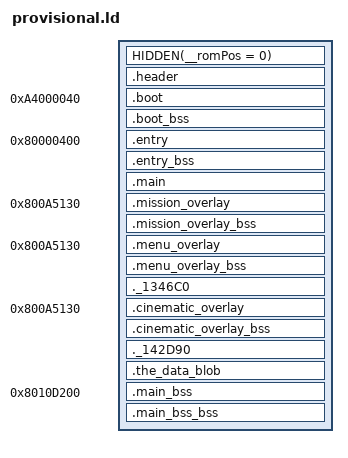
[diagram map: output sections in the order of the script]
SECTIONS
{
    HIDDEN(__romPos = 0);
    header_ROM_START = __romPos;
    header_VRAM = ADDR(.header);
    .header : AT(header_ROM_START) SUBALIGN(16)
    {
        FILL(0x00000000);
        header_DATA_START = .;
        build/asm/header.o(.data);
        header_DATA_END = .;
        header_DATA_SIZE = ABSOLUTE(header_DATA_END - header_DATA_START);
    }
    __romPos += SIZEOF(.header);
    header_ROM_END = __romPos;
    header_VRAM_END = .;

    boot_ROM_START = __romPos;
    boot_VRAM = ADDR(.boot);
    .boot 0xA4000040 : AT(boot_ROM_START) SUBALIGN(16)
    {
        FILL(0x00000000);
        boot_TEXT_START = .;
        build/asm/ipl3_entry.o(.text);
        . = ALIGN(., 16);
        boot_TEXT_END = .;
        boot_TEXT_SIZE = ABSOLUTE(boot_TEXT_END - boot_TEXT_START);
        boot_DATA_START = .;
        build/asm/ipl3_entry.o(.data);
        build/assets/ipl3_font.o(.data);
        . = ALIGN(., 16);
        boot_DATA_END = .;
        boot_DATA_SIZE = ABSOLUTE(boot_DATA_END - boot_DATA_START);
        boot_RODATA_START = .;
        build/asm/ipl3_entry.o(.rodata);
        . = ALIGN(., 16);
        boot_RODATA_END = .;
        boot_RODATA_SIZE = ABSOLUTE(boot_RODATA_END - boot_RODATA_START);
    }
    boot_bss_VRAM = ADDR(.boot_bss);
    .boot_bss (NOLOAD) : SUBALIGN(16)
    {
        FILL(0x00000000);
        boot_BSS_START = .;
        build/asm/ipl3_entry.o(.bss);
        . = ALIGN(., 16);
        boot_BSS_END = .;
        boot_BSS_SIZE = ABSOLUTE(boot_BSS_END - boot_BSS_START);
    }
    __romPos += SIZEOF(.boot);
    __romPos = ALIGN(__romPos, 16);
    . = ALIGN(., 16);
    boot_ROM_END = __romPos;
    boot_VRAM_END = .;

    entry_ROM_START = __romPos;
    entry_VRAM = ADDR(.entry);
    .entry 0x80000400 : AT(entry_ROM_START) SUBALIGN(16)
    {
        FILL(0x00000000);
        entry_TEXT_START = .;
        build/asm/entry_point.o(.text);
        . = ALIGN(., 16);
        entry_TEXT_END = .;
        entry_TEXT_SIZE = ABSOLUTE(entry_TEXT_END - entry_TEXT_START);
        entry_DATA_START = .;
        build/asm/entry_point.o(.data);
        . = ALIGN(., 16);
        entry_DATA_END = .;
        entry_DATA_SIZE = ABSOLUTE(entry_DATA_END - entry_DATA_START);
        entry_RODATA_START = .;
        build/asm/entry_point.o(.rodata);
        . = ALIGN(., 16);
        entry_RODATA_END = .;
        entry_RODATA_SIZE = ABSOLUTE(entry_RODATA_END - entry_RODATA_START);
    }
    entry_bss_VRAM = ADDR(.entry_bss);
    .entry_bss (NOLOAD) : SUBALIGN(16)
    {
        FILL(0x00000000);
        entry_BSS_START = .;
        build/asm/entry_point.o(.bss);
        . = ALIGN(., 16);
        entry_BSS_END = .;
        entry_BSS_SIZE = ABSOLUTE(entry_BSS_END - entry_BSS_START);
    }
    __romPos += SIZEOF(.entry);
    __romPos = ALIGN(__romPos, 16);
    . = ALIGN(., 16);
    entry_ROM_END = __romPos;
    entry_VRAM_END = .;

    main_ROM_START = __romPos;
    main_VRAM = ADDR(.main);
    .main entry_VRAM_END : AT(main_ROM_START) SUBALIGN(16)
    {
        FILL(0x00000000);
        main_RODATA_START = .;
        build/src/main/01720.o(.rodata);
        build/src/main/03310.o(.rodata);
        build/src/main/033C0.o(.rodata);
        build/src/main/03F80.o(.rodata);
        build/src/main/04030.o(.rodata);
        build/src/main/04080.o(.rodata);
        build/src/main/05F80.o(.rodata);
        build/src/main/06170.o(.rodata);
        build/src/main/06560.o(.rodata);
        build/src/main/07800.o(.rodata);
        build/src/main/07F80.o(.rodata);
        build/src/main/080E0.o(.rodata);
        build/src/main/08120.o(.rodata);
        build/src/main/08510.o(.rodata);
        build/asm/main/192E0.o(.rodata);
        build/asm/main/1A410.o(.rodata);
        build/asm/main/1D000.o(.rodata);
        build/asm/main/24570.o(.rodata);
        build/asm/main/24D30.o(.rodata);
        build/asm/main/25480.o(.rodata);
        build/asm/data/main/gspF3DEXMainText.o(.rodata);
        build/src/zlib/adler32.o(.rodata);
        build/asm/data/main/01060.rodata.o(.rodata);
        build/asm/data/main/01070.rodata.o(.rodata);
        build/asm/data/main/01080.rodata.o(.rodata);
        build/asm/data/main/01100.rodata.o(.rodata);
        build/asm/data/main/01120.rodata.o(.rodata);
        build/asm/data/main/013D0.rodata.o(.rodata);
        build/asm/data/main/013F0.rodata.o(.rodata);
        build/asm/data/main/01410.rodata.o(.rodata);
        build/asm/data/main/01590.rodata.o(.rodata);
        build/asm/data/main/01600.rodata.o(.rodata);
        build/src/zlib/inflate.o(.rodata);
        build/src/zlib/infblock.o(.rodata);
        build/src/zlib/infcodes.o(.rodata);
        build/src/zlib/inffast.o(.rodata);
        build/src/zlib/inftrees.o(.rodata);
        build/src/zlib/infutil.o(.rodata);
        build/src/zlib/zutil.o(.rodata);
        build/asm/libultra/io/aisetfreq.o(.rodata);
        build/asm/libultra/io/aisetnextbuf.o(.rodata);
        build/asm/libultra/io/ai.o(.rodata);
        build/asm/libultra/libc/bcmp.o(.rodata);
        build/asm/libultra/libc/bzero.o(.rodata);
        build/asm/libultra/io/conteeplongread.o(.rodata);
        build/asm/libultra/io/conteeplongwrite.o(.rodata);
        build/asm/libultra/io/conteepprobe.o(.rodata);
        build/asm/libultra/io/conteepread.o(.rodata);
        build/asm/libultra/io/conteepwrite.o(.rodata);
        build/asm/libultra/io/contquery.o(.rodata);
        build/asm/libultra/io/contreaddata.o(.rodata);
        build/asm/libultra/io/controller.o(.rodata);
        main_TEXT_START = .;
        build/src/main/01720.o(.text);
        build/src/main/03310.o(.text);
        build/src/main/033C0.o(.text);
        build/src/main/03F80.o(.text);
        build/src/main/04030.o(.text);
        build/src/main/04030.o(.data);
        build/src/main/04080.o(.text);
        build/src/main/05F80.o(.text);
        build/src/main/06170.o(.text);
        build/src/main/06560.o(.text);
        build/src/main/07800.o(.text);
        build/src/main/07F80.o(.text);
        build/src/main/080E0.o(.text);
        build/src/main/08120.o(.text);
        build/src/main/08510.o(.text);
        build/asm/main/192E0.o(.text);
        build/asm/main/1A410.o(.text);
        build/asm/main/1D000.o(.text);
        build/asm/main/24570.o(.text);
        build/asm/main/24D30.o(.text);
        build/asm/main/25480.o(.text);
        build/asm/data/main/gspF3DEXMainText.o(.text);
        build/src/zlib/adler32.o(.text);
        build/src/zlib/inflate.o(.text);
        build/src/zlib/infblock.o(.text);
        build/src/zlib/infcodes.o(.text);
        build/src/zlib/inffast.o(.text);
        build/src/zlib/inftrees.o(.text);
        build/src/zlib/infutil.o(.text);
        build/src/zlib/zutil.o(.text);
        build/asm/libultra/io/aisetfreq.o(.text);
        build/asm/libultra/io/aisetnextbuf.o(.text);
        build/asm/libultra/io/ai.o(.text);
        build/asm/libultra/libc/bcmp.o(.text);
        build/asm/libultra/libc/bzero.o(.text);
        build/asm/libultra/io/conteeplongread.o(.text);
        build/asm/libultra/io/conteeplongwrite.o(.text);
        build/asm/libultra/io/conteepprobe.o(.text);
        build/asm/libultra/io/conteepread.o(.text);
        build/asm/libultra/io/conteepwrite.o(.text);
        build/asm/libultra/io/contquery.o(.text);
        build/asm/libultra/io/contreaddata.o(.text);
        build/asm/libultra/io/controller.o(.text);
        build/asm/libultra/gu/cosf.o(.text);
        build/asm/libultra/os/createmesgqueue.o(.text);
        build/asm/libultra/os/createthread.o(.text);
        build/asm/libultra/os/destroythread.o(.text);
        build/asm/libultra/io/dpctr.o(.text);
        build/asm/libultra/io/dpsetstat.o(.text);
        build/asm/libultra/os/exceptasm.o(.text);
        build/asm/libultra/os/gettime.o(.text);
        build/asm/libultra/os/getcount.o(.text);
        build/asm/libultra/os/initialize.o(.text);
        build/asm/libultra/os/getsr.o(.text);
        build/asm/libultra/os/interrupt.o(.text);
        build/asm/libultra/os/invaldcache.o(.text);
        build/asm/libultra/os/invalicache.o(.text);
        build/asm/libultra/os/jammesg.o(.text);
        build/asm/libultra/io/leointerrupt.o(.text);
        build/asm/libultra/io/epirawdma.o(.text);
        build/asm/libultra/io/leodiskinit.o(.text);
        build/asm/libultra/libc/ll.o(.text);
        build/asm/libultra/os/maptlbrdb.o(.text);
        build/asm/libultra/io/motor.o(.text);
        build/asm/libultra/io/contramread.o(.text);
        build/asm/libultra/io/contramwrite.o(.text);
        build/asm/libultra/io/crc.o(.text);
        build/asm/libultra/gu/mtxcatl.o(.text);
        build/asm/libultra/gu/mtxcatf.o(.text);
        build/asm/libultra/gu/mtxutil.o(.text);
        build/asm/libultra/gu/perspective.o(.text);
        build/asm/libultra/io/pfsallocatefile.o(.text);
        build/asm/libultra/io/contpfs.o(.text);
        build/asm/libultra/io/pfsdeletefile.o(.text);
        build/asm/libultra/io/pfsfreeblocks.o(.text);
        build/asm/libultra/io/pfsgetstatus.o(.text);
        build/asm/libultra/io/pfsinitpak.o(.text);
        build/asm/libultra/io/pfschecker.o(.text);
        build/asm/libultra/io/pfsisplug.o(.text);
        build/asm/libultra/io/pfsreadwritefile.o(.text);
        build/asm/libultra/io/pfsrepairid.o(.text);
        build/asm/libultra/io/pfssearchfile.o(.text);
        build/asm/libultra/io/pidma.o(.text);
        build/asm/libultra/io/pigetcmdq.o(.text);
        build/asm/libultra/io/pimgr.o(.text);
        build/asm/libultra/io/cartrominit.o(.text);
        build/asm/libultra/io/devmgr.o(.text);
        build/asm/libultra/io/epirawread.o(.text);
        build/asm/libultra/io/epirawwrite.o(.text);
        build/asm/libultra/os/getthreadpri.o(.text);
        build/asm/libultra/io/piacs.o(.text);
        build/asm/libultra/io/pirawdma.o(.text);
        build/asm/libultra/io/pirawread.o(.text);
        build/asm/libultra/os/recvmesg.o(.text);
        build/asm/libultra/os/resetglobalintmask.o(.text);
        build/asm/libultra/gu/scale.o(.text);
        build/asm/libultra/os/sendmesg.o(.text);
        build/asm/libultra/os/seteventmesg.o(.text);
        build/asm/libultra/os/setfpccsr.o(.text);
        build/asm/libultra/os/setglobalintmask.o(.text);
        build/asm/libultra/os/setintmask.o(.text);
        build/asm/libultra/os/setsr.o(.text);
        build/asm/libultra/os/setthreadpri.o(.text);
        build/asm/libultra/os/settimer.o(.text);
        build/asm/libultra/io/siacs.o(.text);
        build/asm/libultra/gu/sinf.o(.text);
        build/asm/libultra/io/sirawdma.o(.text);
        build/asm/libultra/io/si.o(.text);
        build/asm/libultra/io/sirawread.o(.text);
        build/asm/libultra/io/sirawwrite.o(.text);
        build/asm/libultra/libc/sprintf.o(.text);
        build/asm/libultra/io/sptask.o(.text);
        build/asm/libultra/libc/bcopy.o(.text);
        build/asm/libultra/io/sp.o(.text);
        build/asm/libultra/io/sprawdma.o(.text);
        build/asm/libultra/io/spsetpc.o(.text);
        build/asm/libultra/io/spsetstat.o(.text);
        build/asm/libultra/io/sptaskyield.o(.text);
        build/asm/libultra/io/sptaskyielded.o(.text);
        build/asm/libultra/io/spgetstat.o(.text);
        build/asm/libultra/os/startthread.o(.text);
        build/asm/libultra/os/stopthread.o(.text);
        build/asm/libultra/libc/string.o(.text);
        build/asm/libultra/os/thread.o(.text);
        build/asm/libultra/os/timerintr.o(.text);
        build/asm/libultra/os/setcompare.o(.text);
        build/asm/libultra/io/viblack.o(.text);
        build/asm/libultra/io/vi.o(.text);
        build/asm/libultra/io/vigetfield.o(.text);
        build/asm/libultra/io/vimgr.o(.text);
        build/asm/libultra/io/vigetcurrcontext.o(.text);
        build/asm/libultra/os/virtualtophysical.o(.text);
        build/asm/libultra/os/probetlb.o(.text);
        build/asm/libultra/io/visetevent.o(.text);
        build/asm/libultra/io/visetmode.o(.text);
        build/asm/libultra/io/visetspecial.o(.text);
        build/asm/libultra/io/viswapbuf.o(.text);
        build/asm/libultra/io/viswapcontext.o(.text);
        build/asm/libultra/os/writebackdcache.o(.text);
        build/asm/libultra/os/writebackdcacheall.o(.text);
        build/asm/libultra/libc/xprintf.o(.text);
        build/asm/libultra/libc/xldtob.o(.text);
        build/asm/libultra/libc/ldiv.o(.text);
        build/asm/libultra/libc/xlitob.o(.text);
        build/asm/libultra/os/yieldthread.o(.text);
        main_DATA_START = .;
        build/asm/data/main/38160.data.o(.data);
        build/asm/data/main/381B0.data.o(.data);
        build/asm/data/main/381C0.data.o(.data);
        build/asm/data/main/38220.data.o(.data);
        build/asm/data/main/38230.data.o(.data);
        build/asm/data/main/38240.data.o(.data);
        build/asm/data/main/38250.data.o(.data);
        build/asm/data/main/383C0.data.o(.data);
        build/asm/data/main/39460.data.o(.data);
        build/asm/data/main/394E0.data.o(.data);
        build/asm/data/main/398F0.data.o(.data);
        build/asm/data/main/gspF3DEXMainData.o(.data);
        build/asm/data/zlib/infblock.data.o(.data);
        build/src/zlib/infcodes.o(.data);
        build/src/zlib/inffast.o(.data);
        build/asm/data/zlib/inftrees.data.o(.data);
        build/asm/data/zlib/infutil.data.o(.data);
        build/asm/data/zlib/zutil.data.o(.data);
        build/asm/libultra/io/aisetfreq.o(.data);
        build/asm/data/libultra/io/aisetnextbuf.data.o(.data);
        build/asm/libultra/io/ai.o(.data);
        build/asm/libultra/libc/bcmp.o(.data);
        build/asm/libultra/libc/bzero.o(.data);
        build/asm/libultra/io/conteeplongread.o(.data);
        build/asm/libultra/io/conteeplongwrite.o(.data);
        build/asm/libultra/io/conteepprobe.o(.data);
        build/asm/libultra/io/conteepread.o(.data);
        build/asm/libultra/io/conteepwrite.o(.data);
        build/asm/libultra/io/contquery.o(.data);
        build/asm/libultra/io/contreaddata.o(.data);
        build/asm/data/libultra/io/controller.data.o(.data);
        build/asm/libultra/gu/cosf.o(.data);
        build/asm/libultra/os/createmesgqueue.o(.data);
        build/asm/libultra/os/createthread.o(.data);
        build/asm/libultra/os/destroythread.o(.data);
        build/asm/libultra/io/dpctr.o(.data);
        build/asm/libultra/io/dpsetstat.o(.data);
        build/asm/data/libultra/os/exceptasm.data.o(.data);
        build/asm/libultra/os/gettime.o(.data);
        build/asm/libultra/os/getcount.o(.data);
        build/asm/data/libultra/os/initialize.data.o(.data);
        build/asm/libultra/os/getsr.o(.data);
        build/asm/libultra/os/interrupt.o(.data);
        build/asm/libultra/os/invaldcache.o(.data);
        build/asm/libultra/os/invalicache.o(.data);
        build/asm/libultra/os/jammesg.o(.data);
        build/asm/libultra/io/leointerrupt.o(.data);
        build/asm/libultra/io/epirawdma.o(.data);
        build/asm/libultra/io/leodiskinit.o(.data);
        build/asm/libultra/libc/ll.o(.data);
        build/asm/libultra/os/maptlbrdb.o(.data);
        build/asm/data/libultra/io/motor.data.o(.data);
        build/asm/libultra/io/contramread.o(.data);
        build/asm/libultra/io/contramwrite.o(.data);
        build/asm/libultra/io/crc.o(.data);
        build/asm/libultra/gu/mtxcatl.o(.data);
        build/asm/libultra/gu/mtxcatf.o(.data);
        build/asm/libultra/gu/mtxutil.o(.data);
        build/asm/libultra/gu/perspective.o(.data);
        build/asm/libultra/io/pfsallocatefile.o(.data);
        build/asm/libultra/io/contpfs.o(.data);
        build/asm/libultra/io/pfsdeletefile.o(.data);
        build/asm/libultra/io/pfsfreeblocks.o(.data);
        build/asm/libultra/io/pfsgetstatus.o(.data);
        build/asm/libultra/io/pfsinitpak.o(.data);
        build/asm/libultra/io/pfschecker.o(.data);
        build/asm/libultra/io/pfsisplug.o(.data);
        build/asm/libultra/io/pfsreadwritefile.o(.data);
        build/asm/libultra/io/pfsrepairid.o(.data);
        build/asm/libultra/io/pfssearchfile.o(.data);
        build/asm/libultra/io/pidma.o(.data);
        build/asm/libultra/io/pigetcmdq.o(.data);
        build/asm/data/libultra/io/pimgr.data.o(.data);
        build/asm/libultra/io/cartrominit.o(.data);
        build/asm/libultra/io/devmgr.o(.data);
        build/asm/libultra/io/epirawread.o(.data);
        build/asm/libultra/io/epirawwrite.o(.data);
        build/asm/libultra/os/getthreadpri.o(.data);
        build/asm/data/libultra/io/piacs.data.o(.data);
        build/asm/libultra/io/pirawdma.o(.data);
        build/asm/libultra/io/pirawread.o(.data);
        build/asm/libultra/os/recvmesg.o(.data);
        build/asm/libultra/os/resetglobalintmask.o(.data);
        build/asm/libultra/gu/scale.o(.data);
        build/asm/libultra/os/sendmesg.o(.data);
        build/asm/libultra/os/seteventmesg.o(.data);
        build/asm/libultra/os/setfpccsr.o(.data);
        build/asm/libultra/os/setglobalintmask.o(.data);
        build/asm/libultra/os/setintmask.o(.data);
        build/asm/libultra/os/setsr.o(.data);
        build/asm/libultra/os/setthreadpri.o(.data);
        build/asm/libultra/os/settimer.o(.data);
        build/asm/data/libultra/io/siacs.data.o(.data);
        build/asm/libultra/gu/sinf.o(.data);
        build/asm/libultra/io/sirawdma.o(.data);
        build/asm/libultra/io/si.o(.data);
        build/asm/libultra/io/sirawread.o(.data);
        build/asm/libultra/io/sirawwrite.o(.data);
        build/asm/libultra/libc/sprintf.o(.data);
        build/asm/libultra/io/sptask.o(.data);
        build/asm/libultra/libc/bcopy.o(.data);
        build/asm/libultra/io/sp.o(.data);
        build/asm/libultra/io/sprawdma.o(.data);
        build/asm/libultra/io/spsetpc.o(.data);
        build/asm/libultra/io/spsetstat.o(.data);
        build/asm/libultra/io/sptaskyield.o(.data);
        build/asm/libultra/io/sptaskyielded.o(.data);
        build/asm/libultra/io/spgetstat.o(.data);
        build/asm/libultra/os/startthread.o(.data);
        build/asm/libultra/os/stopthread.o(.data);
        build/asm/libultra/libc/string.o(.data);
        build/asm/data/libultra/os/thread.data.o(.data);
        build/asm/data/libultra/os/timerintr.data.o(.data);
        build/asm/libultra/os/setcompare.o(.data);
        build/asm/libultra/io/viblack.o(.data);
        build/asm/data/libultra/io/vi.data.o(.data);
        build/asm/libultra/io/vigetfield.o(.data);
        build/asm/data/libultra/io/vimgr.data.o(.data);
        build/asm/libultra/io/vigetcurrcontext.o(.data);
        build/asm/libultra/os/virtualtophysical.o(.data);
        build/asm/libultra/os/probetlb.o(.data);
        build/asm/libultra/io/visetevent.o(.data);
        build/asm/libultra/io/visetmode.o(.data);
        build/asm/libultra/io/visetspecial.o(.data);
        build/asm/libultra/io/viswapbuf.o(.data);
        build/asm/libultra/io/viswapcontext.o(.data);
        build/asm/libultra/os/writebackdcache.o(.data);
        build/asm/libultra/os/writebackdcacheall.o(.data);
        build/asm/data/libultra/vimodes/vimodempallan1.data.o(.data);
        build/asm/data/libultra/vimodes/vimodentsclan1.data.o(.data);
        build/asm/data/libultra/vimodes/vimodepallan1.data.o(.data);
        build/asm/data/libultra/io/vitbl.data.o(.data);
        build/asm/data/libultra/libc/xprintf.data.o(.data);
        build/asm/libultra/libc/xldtob.o(.data);
        build/asm/libultra/libc/ldiv.o(.data);
        build/asm/data/libultra/libc/xlitob.data.o(.data);
        build/asm/libultra/os/yieldthread.o(.data);
        build/asm/data/main/rspbootText.o(.data);
        build/asm/main/832A0.o(.data);
        build/asm/main/94A80.o(.data);
        build/asm/main/94F50.o(.data);
        build/asm/main/97D20.o(.data);
        build/asm/main/98960.o(.data);
        build/asm/main/9A850.o(.data);
        build/asm/data/main/aspMainText.o(.data);
        build/asm/main/9BB60.o(.data);
        build/asm/main/9CED0.o(.data);
        build/asm/main/9E3D0.o(.data);
        build/asm/data/libultra/gu/cosf.rodata.o(.rodata);
        build/asm/libultra/os/createmesgqueue.o(.rodata);
        build/asm/libultra/os/createthread.o(.rodata);
        build/asm/libultra/os/destroythread.o(.rodata);
        build/asm/libultra/io/dpctr.o(.rodata);
        build/asm/libultra/io/dpsetstat.o(.rodata);
        build/asm/data/libultra/os/exceptasm.rodata.o(.rodata);
        build/asm/libultra/os/gettime.o(.rodata);
        build/asm/libultra/os/getcount.o(.rodata);
        build/asm/libultra/os/initialize.o(.rodata);
        build/asm/libultra/os/getsr.o(.rodata);
        build/asm/libultra/os/interrupt.o(.rodata);
        build/asm/libultra/os/invaldcache.o(.rodata);
        build/asm/libultra/os/invalicache.o(.rodata);
        build/asm/libultra/os/jammesg.o(.rodata);
        build/asm/libultra/io/leointerrupt.o(.rodata);
        build/asm/libultra/io/epirawdma.o(.rodata);
        build/asm/libultra/io/leodiskinit.o(.rodata);
        build/asm/libultra/libc/ll.o(.rodata);
        build/asm/libultra/os/maptlbrdb.o(.rodata);
        build/asm/libultra/io/motor.o(.rodata);
        build/asm/libultra/io/contramread.o(.rodata);
        build/asm/libultra/io/contramwrite.o(.rodata);
        build/asm/libultra/io/crc.o(.rodata);
        build/asm/libultra/gu/mtxcatl.o(.rodata);
        build/asm/libultra/gu/mtxcatf.o(.rodata);
        build/asm/libultra/gu/mtxutil.o(.rodata);
        build/asm/data/libultra/gu/libm_vals.rodata.o(.rodata);
        build/asm/data/libultra/gu/perspective.rodata.o(.rodata);
        build/asm/libultra/io/pfsallocatefile.o(.rodata);
        build/asm/libultra/io/contpfs.o(.rodata);
        build/asm/libultra/io/pfsdeletefile.o(.rodata);
        build/asm/libultra/io/pfsfreeblocks.o(.rodata);
        build/asm/libultra/io/pfsgetstatus.o(.rodata);
        build/asm/libultra/io/pfsinitpak.o(.rodata);
        build/asm/libultra/io/pfschecker.o(.rodata);
        build/asm/libultra/io/pfsisplug.o(.rodata);
        build/asm/libultra/io/pfsreadwritefile.o(.rodata);
        build/asm/libultra/io/pfsrepairid.o(.rodata);
        build/asm/libultra/io/pfssearchfile.o(.rodata);
        build/asm/libultra/io/pidma.o(.rodata);
        build/asm/libultra/io/pigetcmdq.o(.rodata);
        build/asm/libultra/io/pimgr.o(.rodata);
        build/asm/libultra/io/cartrominit.o(.rodata);
        build/asm/data/libultra/io/devmgr.rodata.o(.rodata);
        build/asm/libultra/io/epirawread.o(.rodata);
        build/asm/libultra/io/epirawwrite.o(.rodata);
        build/asm/libultra/os/getthreadpri.o(.rodata);
        build/asm/libultra/io/piacs.o(.rodata);
        build/asm/libultra/io/pirawdma.o(.rodata);
        build/asm/libultra/io/pirawread.o(.rodata);
        build/asm/libultra/os/recvmesg.o(.rodata);
        build/asm/libultra/os/resetglobalintmask.o(.rodata);
        build/asm/libultra/gu/scale.o(.rodata);
        build/asm/libultra/os/sendmesg.o(.rodata);
        build/asm/libultra/os/seteventmesg.o(.rodata);
        build/asm/libultra/os/setfpccsr.o(.rodata);
        build/asm/libultra/os/setglobalintmask.o(.rodata);
        build/asm/data/libultra/os/setintmask.rodata.o(.rodata);
        build/asm/libultra/os/setsr.o(.rodata);
        build/asm/libultra/os/setthreadpri.o(.rodata);
        build/asm/libultra/os/settimer.o(.rodata);
        build/asm/libultra/io/siacs.o(.rodata);
        build/asm/data/libultra/gu/sinf.rodata.o(.rodata);
        build/asm/libultra/io/sirawdma.o(.rodata);
        build/asm/libultra/io/si.o(.rodata);
        build/asm/libultra/io/sirawread.o(.rodata);
        build/asm/libultra/io/sirawwrite.o(.rodata);
        build/asm/libultra/libc/sprintf.o(.rodata);
        build/asm/libultra/io/sptask.o(.rodata);
        build/asm/libultra/libc/bcopy.o(.rodata);
        build/asm/libultra/io/sp.o(.rodata);
        build/asm/libultra/io/sprawdma.o(.rodata);
        build/asm/libultra/io/spsetpc.o(.rodata);
        build/asm/libultra/io/spsetstat.o(.rodata);
        build/asm/libultra/io/sptaskyield.o(.rodata);
        build/asm/libultra/io/sptaskyielded.o(.rodata);
        build/asm/libultra/io/spgetstat.o(.rodata);
        build/asm/libultra/os/startthread.o(.rodata);
        build/asm/libultra/os/stopthread.o(.rodata);
        build/asm/libultra/libc/string.o(.rodata);
        build/asm/libultra/os/thread.o(.rodata);
        build/asm/libultra/os/timerintr.o(.rodata);
        build/asm/libultra/os/setcompare.o(.rodata);
        build/asm/libultra/io/viblack.o(.rodata);
        build/asm/libultra/io/vi.o(.rodata);
        build/asm/libultra/io/vigetfield.o(.rodata);
        build/asm/libultra/io/vimgr.o(.rodata);
        build/asm/libultra/io/vigetcurrcontext.o(.rodata);
        build/asm/libultra/os/virtualtophysical.o(.rodata);
        build/asm/libultra/os/probetlb.o(.rodata);
        build/asm/libultra/io/visetevent.o(.rodata);
        build/asm/libultra/io/visetmode.o(.rodata);
        build/asm/libultra/io/visetspecial.o(.rodata);
        build/asm/libultra/io/viswapbuf.o(.rodata);
        build/asm/libultra/io/viswapcontext.o(.rodata);
        build/asm/libultra/os/writebackdcache.o(.rodata);
        build/asm/libultra/os/writebackdcacheall.o(.rodata);
        build/asm/data/libultra/libc/xprintf.rodata.o(.rodata);
        build/asm/data/libultra/libc/xldtob.rodata.o(.rodata);
        build/asm/libultra/libc/ldiv.o(.rodata);
        build/asm/libultra/libc/xlitob.o(.rodata);
        build/asm/libultra/os/yieldthread.o(.rodata);
        build/asm/data/main/rspbootText.o(.rodata);
        build/asm/main/832A0.o(.rodata);
        build/asm/main/94A80.o(.rodata);
        build/asm/main/94F50.o(.rodata);
        build/asm/main/97D20.o(.rodata);
        build/asm/main/98960.o(.rodata);
        build/asm/main/9A850.o(.rodata);
        build/asm/data/main/aspMainText.o(.rodata);
        build/asm/main/9BB60.o(.rodata);
        build/asm/main/9CED0.o(.rodata);
        build/asm/main/9E3D0.o(.rodata);
        build/asm/data/main/3AFE0.rodata.o(.rodata);
        build/asm/data/main/3B0D0.rodata.o(.rodata);
        build/asm/data/main/3B210.rodata.o(.rodata);
        build/asm/data/main/3B240.rodata.o(.rodata);
        build/asm/data/main/3B3E0.rodata.o(.rodata);
        build/asm/data/main/3B420.rodata.o(.rodata);
        build/asm/data/main/3B4C0.rodata.o(.rodata);
        build/asm/data/main/3B4D0.rodata.o(.rodata);
        build/asm/data/main/3B7E0.rodata.o(.rodata);
        build/asm/data/main/3B8D0.rodata.o(.rodata);
        build/asm/data/main/3B920.rodata.o(.rodata);
        build/asm/data/main/3B9C0.rodata.o(.rodata);
        build/asm/data/main/3BE30.rodata.o(.rodata);
        build/asm/data/main/3BF00.rodata.o(.rodata);
        build/asm/data/main/3C010.rodata.o(.rodata);
        build/asm/data/main/3C430.rodata.o(.rodata);
        build/asm/data/main/3CE60.rodata.o(.rodata);
        build/asm/data/main/3CEE0.rodata.o(.rodata);
        build/asm/data/main/3D3D0.rodata.o(.rodata);
        build/asm/data/main/3D4D0.rodata.o(.rodata);
        build/src/main/6B8B0.o(.rodata);
        build/asm/data/main/3D560.rodata.o(.rodata);
        build/asm/data/main/3D5D0.rodata.o(.rodata);
        build/src/main/6E500.o(.rodata);
        build/asm/data/main/3D770.rodata.o(.rodata);
        build/asm/data/main/3DAF0.rodata.o(.rodata);
        build/asm/data/main/3E100.rodata.o(.rodata);
        build/asm/data/main/3E230.rodata.o(.rodata);
        build/asm/data/main/3EA70.rodata.o(.rodata);
        build/asm/data/main/3EAF0.rodata.o(.rodata);
        build/asm/data/main/3EB00.rodata.o(.rodata);
        build/src/main/3EB20.o(.text);
        build/src/main/3EBA0.o(.text);
        build/src/main/3F160.o(.text);
        build/src/main/40F10.o(.text);
        build/src/main/42AF0.o(.text);
        build/src/main/463D0.o(.text);
        build/src/main/47220.o(.text);
        build/src/main/4A300.o(.text);
        build/src/main/4D900.o(.text);
        build/src/main/544B0.o(.text);
        build/src/main/55250.o(.text);
        build/src/main/55AF0.o(.text);
        build/src/main/561F0.o(.text);
        build/src/main/562A0.o(.text);
        build/src/main/56630.o(.text);
        build/src/main/56F50.o(.text);
        build/src/main/5A750.o(.text);
        build/src/main/5AD20.o(.text);
        build/src/main/5D220.o(.text);
        build/src/main/5FA70.o(.text);
        build/src/main/61FC0.o(.text);
        build/src/main/64EA0.o(.text);
        build/src/main/65540.o(.text);
        build/src/main/66660.o(.text);
        build/src/main/66FB0.o(.text);
        build/src/main/68990.o(.text);
        build/src/main/6A6F0.o(.text);
        build/src/main/6B8B0.o(.text);
        build/src/main/6C310.o(.text);
        build/src/main/6E500.o(.text);
        build/src/main/700B0.o(.text);
        build/src/main/738F0.o(.text);
        build/src/main/79E80.o(.text);
        build/src/main/7A8E0.o(.text);
        build/src/main/7ACF0.o(.text);
        build/src/main/7B470.o(.text);
        build/src/main/7CEA0.o(.text);
        build/src/main/82E70.o(.text);
        build/asm/data/main/rspbootText.o(.text);
        build/asm/main/832A0.o(.text);
        build/asm/main/94A80.o(.text);
        build/asm/main/94F50.o(.text);
        build/asm/main/97D20.o(.text);
        build/asm/main/98960.o(.text);
        build/asm/main/9A850.o(.text);
        build/asm/data/main/aspMainText.o(.text);
        build/asm/main/9BB60.o(.text);
        build/asm/main/9CED0.o(.text);
        build/asm/main/9E3D0.o(.text);
        . = ALIGN(., 16);
        main_TEXT_END = .;
        main_TEXT_SIZE = ABSOLUTE(main_TEXT_END - main_TEXT_START);
        build/src/main/01720.o(.data);
        build/src/main/03310.o(.data);
        build/src/main/033C0.o(.data);
        build/src/main/03F80.o(.data);
        build/src/main/04080.o(.data);
        build/src/main/05F80.o(.data);
        build/src/main/06170.o(.data);
        build/src/main/06560.o(.data);
        build/src/main/07800.o(.data);
        build/src/main/07F80.o(.data);
        build/src/main/080E0.o(.data);
        build/src/main/08120.o(.data);
        build/src/main/08510.o(.data);
        build/asm/main/192E0.o(.data);
        build/asm/main/1A410.o(.data);
        build/asm/main/1D000.o(.data);
        build/asm/main/24570.o(.data);
        build/asm/main/24D30.o(.data);
        build/asm/main/25480.o(.data);
        build/asm/data/main/gspF3DEXMainText.o(.data);
        build/src/zlib/adler32.o(.data);
        build/src/zlib/inflate.o(.data);
        build/asm/data/main/9E9D0.data.o(.data);
        build/asm/data/main/9EAC0.data.o(.data);
        build/asm/data/main/9EAD0.data.o(.data);
        build/asm/data/main/9EAE0.data.o(.data);
        build/asm/data/main/9F810.data.o(.data);
        build/asm/data/main/9F850.data.o(.data);
        build/asm/data/main/9F8A0.data.o(.data);
        build/asm/data/main/9F8B0.data.o(.data);
        build/asm/data/main/9F960.data.o(.data);
        build/asm/data/main/A0850.data.o(.data);
        build/asm/data/main/A08D0.data.o(.data);
        build/asm/data/main/A0BE0.data.o(.data);
        build/src/main/6B8B0.o(.data);
        build/asm/data/main/A15C0.data.o(.data);
        build/src/main/6E500.o(.data);
        build/asm/data/main/A1690.data.o(.data);
        build/asm/data/main/A1970.data.o(.data);
        build/asm/data/main/A1980.data.o(.data);
        build/asm/data/main/A1990.data.o(.data);
        build/src/main/82E70.o(.data);
        build/asm/data/main/A1B50.data.o(.data);
        build/asm/data/main/A2360.data.o(.data);
        build/asm/data/main/A2380.data.o(.data);
        build/asm/data/main/A2390.data.o(.data);
        build/asm/data/main/aspMainData.o(.data);
        . = ALIGN(., 16);
        main_DATA_END = .;
        main_DATA_SIZE = ABSOLUTE(main_DATA_END - main_DATA_START);
        build/asm/data/main/A5D20.data.o(.data);
        . = ALIGN(., 16);
        main_RODATA_END = .;
        main_RODATA_SIZE = ABSOLUTE(main_RODATA_END - main_RODATA_START);
    }
    __romPos += SIZEOF(.main);
    __romPos = ALIGN(__romPos, 16);
    . = ALIGN(., 16);
    main_ROM_END = __romPos;
    main_VRAM_END = .;

    mission_overlay_ROM_START = __romPos;
    mission_overlay_BASEROM_START = mission_overlay_ROM_START + 0xB0000000;
    mission_overlay_VRAM = ADDR(.mission_overlay);
    .mission_overlay 0x800A5130 : AT(mission_overlay_ROM_START) SUBALIGN(16)
    {
        FILL(0x00000000);
        mission_overlay_RODATA_START = .;
        build/src/mission_overlay/0AA780.o(.rodata);
        build/src/mission_overlay/0AB2D0.o(.rodata);
        build/src/mission_overlay/0AB6E0.o(.rodata);
        build/src/mission_overlay/0ADF80.o(.rodata);
        build/src/mission_overlay/0AEFF0.o(.rodata);
        build/src/mission_overlay/0B4EC0.o(.rodata);
        build/src/mission_overlay/0B64C0.o(.rodata);
        build/src/mission_overlay/0B81D0.o(.rodata);
        build/src/mission_overlay/0B9600.o(.rodata);
        build/src/mission_overlay/0BAFF0.o(.rodata);
        build/src/mission_overlay/0BC930.o(.rodata);
        build/src/mission_overlay/0BD840.o(.rodata);
        build/src/mission_overlay/0BE650.o(.rodata);
        build/src/mission_overlay/0BF800.o(.rodata);
        build/src/mission_overlay/0C00A0.o(.rodata);
        build/src/mission_overlay/0C0390.o(.rodata);
        build/src/mission_overlay/0C4DB0.o(.rodata);
        build/src/mission_overlay/0C70B0.o(.rodata);
        build/src/mission_overlay/0C84A0.o(.rodata);
        build/src/mission_overlay/0C89C0.o(.rodata);
        build/src/mission_overlay/0CAE70.o(.rodata);
        build/src/mission_overlay/0CC9A0.o(.rodata);
        build/src/mission_overlay/0CFB20.o(.rodata);
        build/src/mission_overlay/0D38A0.o(.rodata);
        build/src/mission_overlay/0D5AD0.o(.rodata);
        build/src/mission_overlay/0D6BE0.o(.rodata);
        build/src/mission_overlay/0D8450.o(.rodata);
        build/src/mission_overlay/0DCF00.o(.rodata);
        build/src/mission_overlay/0DDED0.o(.rodata);
        build/src/mission_overlay/0E0790.o(.rodata);
        build/src/mission_overlay/0E4C70.o(.rodata);
        build/src/mission_overlay/0E5080.o(.rodata);
        build/src/mission_overlay/0E7DD0.o(.rodata);
        build/src/mission_overlay/0E9640.o(.rodata);
        build/src/mission_overlay/0EA6E0.o(.rodata);
        build/src/mission_overlay/0EC590.o(.rodata);
        build/src/mission_overlay/0ECD10.o(.rodata);
        build/src/mission_overlay/0ED2F0.o(.rodata);
        build/src/mission_overlay/0EDA10.o(.rodata);
        build/src/mission_overlay/0EDD50.o(.rodata);
        build/src/mission_overlay/0F0980.o(.rodata);
        build/src/mission_overlay/0F09E0.o(.rodata);
        build/src/mission_overlay/0F3E90.o(.rodata);
        build/src/mission_overlay/0FAE50.o(.rodata);
        build/src/mission_overlay/0FCA20.o(.rodata);
        build/src/mission_overlay/0FFB10.o(.rodata);
        build/src/mission_overlay/100A00.o(.rodata);
        build/src/mission_overlay/level_objective_handling/lv_0.o(.rodata);
        build/src/mission_overlay/level_objective_handling/lv_1.o(.rodata);
        build/src/mission_overlay/level_objective_handling/lv_2.o(.rodata);
        build/src/mission_overlay/level_objective_handling/lv_3.o(.rodata);
        build/src/mission_overlay/level_objective_handling/lv_4.o(.rodata);
        build/src/mission_overlay/level_objective_handling/lv_5.o(.rodata);
        build/src/mission_overlay/level_objective_handling/lv_6.o(.rodata);
        build/src/mission_overlay/level_objective_handling/lv_7.o(.rodata);
        build/src/mission_overlay/level_objective_handling/lv_8.o(.rodata);
        build/src/mission_overlay/level_objective_handling/lv_9.o(.rodata);
        build/src/mission_overlay/level_objective_handling/lv_a.o(.rodata);
        build/src/mission_overlay/level_objective_handling/lv_b.o(.rodata);
        build/src/mission_overlay/level_objective_handling/lv_c.o(.rodata);
        build/src/mission_overlay/level_objective_handling/lv_d.o(.rodata);
        build/src/mission_overlay/level_objective_handling/lv_e.o(.rodata);
        build/src/mission_overlay/level_objective_handling/lv_f.o(.rodata);
        build/src/mission_overlay/level_objective_handling/lv_g.o(.rodata);
        build/src/mission_overlay/level_objective_handling/lv_h.o(.rodata);
        build/src/mission_overlay/level_objective_handling/lv_i.o(.rodata);
        build/src/mission_overlay/level_objective_handling/lv_k.o(.rodata);
        build/src/mission_overlay/level_objective_handling/lv_j.o(.rodata);
        . = ALIGN(., 16);
        mission_overlay_RODATA_END = .;
        mission_overlay_RODATA_SIZE = ABSOLUTE(mission_overlay_RODATA_END - mission_overlay_RODATA_START);
        mission_overlay_TEXT_START = .;
        build/src/mission_overlay/0AA780.o(.text);
        build/src/mission_overlay/0AB2D0.o(.text);
        build/src/mission_overlay/0AB6E0.o(.text);
        build/src/mission_overlay/0ADF80.o(.text);
        build/src/mission_overlay/0AEFF0.o(.text);
        build/src/mission_overlay/0B4EC0.o(.text);
        build/src/mission_overlay/0B64C0.o(.text);
        build/src/mission_overlay/0B81D0.o(.text);
        build/src/mission_overlay/0B9600.o(.text);
        build/src/mission_overlay/0BAFF0.o(.text);
        build/src/mission_overlay/0BC930.o(.text);
        build/src/mission_overlay/0BD840.o(.text);
        build/src/mission_overlay/0BE650.o(.text);
        build/src/mission_overlay/0BF800.o(.text);
        build/src/mission_overlay/0C00A0.o(.text);
        build/src/mission_overlay/0C0390.o(.text);
        build/src/mission_overlay/0C4DB0.o(.text);
        build/src/mission_overlay/0C70B0.o(.text);
        build/src/mission_overlay/0C84A0.o(.text);
        build/src/mission_overlay/0C89C0.o(.text);
        build/src/mission_overlay/0CAE70.o(.text);
        build/src/mission_overlay/0CC9A0.o(.text);
        build/src/mission_overlay/0CFB20.o(.text);
        build/src/mission_overlay/0D38A0.o(.text);
        build/src/mission_overlay/0D5AD0.o(.text);
        build/src/mission_overlay/0D6BE0.o(.text);
        build/src/mission_overlay/0D8450.o(.text);
        build/src/mission_overlay/0DCF00.o(.text);
        build/src/mission_overlay/0DDED0.o(.text);
        build/src/mission_overlay/0E0790.o(.text);
        build/src/mission_overlay/0E4C70.o(.text);
        build/src/mission_overlay/0E5080.o(.text);
        build/src/mission_overlay/0E7DD0.o(.text);
        build/src/mission_overlay/0E9640.o(.text);
        build/src/mission_overlay/0EA6E0.o(.text);
        build/src/mission_overlay/0EC590.o(.text);
        build/src/mission_overlay/0ECD10.o(.text);
        build/src/mission_overlay/0ED2F0.o(.text);
        build/src/mission_overlay/0EDA10.o(.text);
        build/src/mission_overlay/0EDD50.o(.text);
        build/src/mission_overlay/0F0980.o(.text);
        build/src/mission_overlay/0F09E0.o(.text);
        build/src/mission_overlay/0F3E90.o(.text);
        build/src/mission_overlay/0FAE50.o(.text);
        build/src/mission_overlay/0FCA20.o(.text);
        build/src/mission_overlay/0FFB10.o(.text);
        build/src/mission_overlay/100A00.o(.text);
        build/src/mission_overlay/level_objective_handling/lv_0.o(.text);
        build/src/mission_overlay/level_objective_handling/lv_1.o(.text);
        build/src/mission_overlay/level_objective_handling/lv_2.o(.text);
        build/src/mission_overlay/level_objective_handling/lv_3.o(.text);
        build/src/mission_overlay/level_objective_handling/lv_4.o(.text);
        build/src/mission_overlay/level_objective_handling/lv_5.o(.text);
        build/src/mission_overlay/level_objective_handling/lv_6.o(.text);
        build/src/mission_overlay/level_objective_handling/lv_7.o(.text);
        build/src/mission_overlay/level_objective_handling/lv_8.o(.text);
        build/src/mission_overlay/level_objective_handling/lv_9.o(.text);
        build/src/mission_overlay/level_objective_handling/lv_a.o(.text);
        build/src/mission_overlay/level_objective_handling/lv_b.o(.text);
        build/src/mission_overlay/level_objective_handling/lv_c.o(.text);
        build/src/mission_overlay/level_objective_handling/lv_d.o(.text);
        build/src/mission_overlay/level_objective_handling/lv_e.o(.text);
        build/src/mission_overlay/level_objective_handling/lv_f.o(.text);
        build/src/mission_overlay/level_objective_handling/lv_g.o(.text);
        build/src/mission_overlay/level_objective_handling/lv_h.o(.text);
        build/src/mission_overlay/level_objective_handling/lv_i.o(.text);
        build/src/mission_overlay/level_objective_handling/lv_k.o(.text);
        build/src/mission_overlay/level_objective_handling/lv_j.o(.text);
        . = ALIGN(., 16);
        mission_overlay_TEXT_END = .;
        mission_overlay_TEXT_SIZE = ABSOLUTE(mission_overlay_TEXT_END - mission_overlay_TEXT_START);
        mission_overlay_DATA_START = .;
        build/src/mission_overlay/0AA780.o(.data);
        build/src/mission_overlay/0AB2D0.o(.data);
        build/asm/data/mission_overlay/0AB6E0.data.o(.data);
        build/asm/data/mission_overlay/0ADF80.data.o(.data);
        build/asm/data/mission_overlay/0AEFF0.data.o(.data);
        build/asm/data/mission_overlay/0B4EC0.data.o(.data);
        build/asm/data/mission_overlay/0B64C0.data.o(.data);
        build/asm/data/mission_overlay/0B81D0.data.o(.data);
        build/asm/data/mission_overlay/0B9600.data.o(.data);
        build/asm/data/mission_overlay/0BAFF0.data.o(.data);
        build/asm/data/mission_overlay/0BC930.data.o(.data);
        build/asm/data/mission_overlay/0BD840.data.o(.data);
        build/asm/data/mission_overlay/0BE650.data.o(.data);
        build/asm/data/mission_overlay/0BF800.data.o(.data);
        build/asm/data/mission_overlay/0C00A0.data.o(.data);
        build/asm/data/mission_overlay/0C0390.data.o(.data);
        build/asm/data/mission_overlay/0C4DB0.data.o(.data);
        build/asm/data/mission_overlay/0C70B0.data.o(.data);
        build/src/mission_overlay/0C84A0.o(.data);
        build/asm/data/mission_overlay/0C89C0.data.o(.data);
        build/asm/data/mission_overlay/0CAE70.data.o(.data);
        build/asm/data/mission_overlay/0CC9A0.data.o(.data);
        build/asm/data/mission_overlay/0CFB20.data.o(.data);
        build/asm/data/mission_overlay/0D38A0.data.o(.data);
        build/src/mission_overlay/0D5AD0.o(.data);
        build/asm/data/mission_overlay/0D6BE0.data.o(.data);
        build/asm/data/mission_overlay/0D8450.data.o(.data);
        build/asm/data/mission_overlay/0DCF00.data.o(.data);
        build/asm/data/mission_overlay/0DDED0.data.o(.data);
        build/asm/data/mission_overlay/0E0790.data.o(.data);
        build/src/mission_overlay/0E4C70.o(.data);
        build/asm/data/mission_overlay/0E5080.data.o(.data);
        build/asm/data/mission_overlay/0E7DD0.data.o(.data);
        build/asm/data/mission_overlay/0E9640.data.o(.data);
        build/asm/data/mission_overlay/0EA6E0.data.o(.data);
        build/src/mission_overlay/0EC590.o(.data);
        build/src/mission_overlay/0ECD10.o(.data);
        build/src/mission_overlay/0ED2F0.o(.data);
        build/src/mission_overlay/0EDA10.o(.data);
        build/asm/data/mission_overlay/0EDD50.data.o(.data);
        build/src/mission_overlay/0F0980.o(.data);
        build/asm/data/mission_overlay/0F09E0.data.o(.data);
        build/src/mission_overlay/0F3E90.o(.data);
        build/asm/data/mission_overlay/0FAE50.data.o(.data);
        build/asm/data/mission_overlay/0FCA20.data.o(.data);
        build/asm/data/mission_overlay/0FFB10.data.o(.data);
        build/asm/data/mission_overlay/100A00.data.o(.data);
        build/asm/data/mission_overlay/level_objective_handling/lv_0.data.o(.data);
        build/asm/data/mission_overlay/level_objective_handling/lv_1.data.o(.data);
        build/asm/data/mission_overlay/level_objective_handling/lv_2.data.o(.data);
        build/src/mission_overlay/level_objective_handling/lv_3.o(.data);
        build/src/mission_overlay/level_objective_handling/lv_4.o(.data);
        build/src/mission_overlay/level_objective_handling/lv_5.o(.data);
        build/src/mission_overlay/level_objective_handling/lv_6.o(.data);
        build/src/mission_overlay/level_objective_handling/lv_7.o(.data);
        build/src/mission_overlay/level_objective_handling/lv_8.o(.data);
        build/src/mission_overlay/level_objective_handling/lv_9.o(.data);
        build/src/mission_overlay/level_objective_handling/lv_a.o(.data);
        build/src/mission_overlay/level_objective_handling/lv_b.o(.data);
        build/src/mission_overlay/level_objective_handling/lv_c.o(.data);
        build/src/mission_overlay/level_objective_handling/lv_d.o(.data);
        build/src/mission_overlay/level_objective_handling/lv_e.o(.data);
        build/src/mission_overlay/level_objective_handling/lv_f.o(.data);
        build/src/mission_overlay/level_objective_handling/lv_g.o(.data);
        build/src/mission_overlay/level_objective_handling/lv_h.o(.data);
        build/src/mission_overlay/level_objective_handling/lv_i.o(.data);
        build/src/mission_overlay/level_objective_handling/lv_k.o(.data);
        build/src/mission_overlay/level_objective_handling/lv_j.o(.data);
        . = ALIGN(., 16);
        mission_overlay_DATA_END = .;
        mission_overlay_DATA_SIZE = ABSOLUTE(mission_overlay_DATA_END - mission_overlay_DATA_START);
    }
    mission_overlay_bss_VRAM = ADDR(.mission_overlay_bss);
    .mission_overlay_bss (NOLOAD) : SUBALIGN(16)
    {
        FILL(0x00000000);
        mission_overlay_BSS_START = .;
        build/src/mission_overlay/0AA780.o(.bss);
        build/src/mission_overlay/0AB2D0.o(.bss);
        build/asm/data/mission_overlay/0AB6E0.bss.o(.bss);
        build/asm/data/mission_overlay/0ADF80.bss.o(.bss);
        build/asm/data/mission_overlay/0AEFF0.bss.o(.bss);
        build/asm/data/mission_overlay/0B4EC0.bss.o(.bss);
        build/src/mission_overlay/0B64C0.o(.bss);
        build/src/mission_overlay/0B81D0.o(.bss);
        build/src/mission_overlay/0B9600.o(.bss);
        build/src/mission_overlay/0BAFF0.o(.bss);
        build/src/mission_overlay/0BC930.o(.bss);
        build/src/mission_overlay/0BD840.o(.bss);
        build/src/mission_overlay/0BE650.o(.bss);
        build/asm/data/mission_overlay/0BF800.bss.o(.bss);
        build/src/mission_overlay/0C00A0.o(.bss);
        build/asm/data/mission_overlay/0C0390.bss.o(.bss);
        build/asm/data/mission_overlay/0C4DB0.bss.o(.bss);
        build/asm/data/mission_overlay/0C70B0.bss.o(.bss);
        build/src/mission_overlay/0C84A0.o(.bss);
        build/src/mission_overlay/0C89C0.o(.bss);
        build/src/mission_overlay/0CAE70.o(.bss);
        build/src/mission_overlay/0CC9A0.o(.bss);
        build/src/mission_overlay/0CFB20.o(.bss);
        build/src/mission_overlay/0D38A0.o(.bss);
        build/src/mission_overlay/0D5AD0.o(.bss);
        build/src/mission_overlay/0D6BE0.o(.bss);
        build/src/mission_overlay/0D8450.o(.bss);
        build/src/mission_overlay/0DCF00.o(.bss);
        build/asm/data/mission_overlay/0DDED0.bss.o(.bss);
        build/asm/data/mission_overlay/0E0790.bss.o(.bss);
        build/src/mission_overlay/0E4C70.o(.bss);
        build/src/mission_overlay/0E5080.o(.bss);
        build/src/mission_overlay/0E7DD0.o(.bss);
        build/src/mission_overlay/0E9640.o(.bss);
        build/asm/data/mission_overlay/0EA6E0.bss.o(.bss);
        build/src/mission_overlay/0EC590.o(.bss);
        build/asm/data/mission_overlay/0ECD10.bss.o(.bss);
        build/src/mission_overlay/0ED2F0.o(.bss);
        build/src/mission_overlay/0EDA10.o(.bss);
        build/asm/data/mission_overlay/0EDD50.bss.o(.bss);
        build/src/mission_overlay/0F0980.o(.bss);
        build/asm/data/mission_overlay/0F09E0.bss.o(.bss);
        build/asm/data/mission_overlay/0F3E90.bss.o(.bss);
        build/asm/data/mission_overlay/0FAE50.bss.o(.bss);
        build/src/mission_overlay/0FCA20.o(.bss);
        build/src/mission_overlay/0FFB10.o(.bss);
        build/asm/data/mission_overlay/100A00.bss.o(.bss);
        build/src/mission_overlay/level_objective_handling/lv_0.o(.bss);
        build/asm/data/mission_overlay/level_objective_handling/lv_1.bss.o(.bss);
        build/src/mission_overlay/level_objective_handling/lv_2.o(.bss);
        build/asm/data/mission_overlay/level_objective_handling/lv_3.bss.o(.bss);
        build/asm/data/mission_overlay/level_objective_handling/lv_4.bss.o(.bss);
        build/asm/data/mission_overlay/level_objective_handling/lv_5.bss.o(.bss);
        build/src/mission_overlay/level_objective_handling/lv_6.o(.bss);
        build/asm/data/mission_overlay/level_objective_handling/lv_7.bss.o(.bss);
        build/asm/data/mission_overlay/level_objective_handling/lv_8.bss.o(.bss);
        build/asm/data/mission_overlay/level_objective_handling/lv_9.bss.o(.bss);
        build/src/mission_overlay/level_objective_handling/lv_a.o(.bss);
        build/asm/data/mission_overlay/level_objective_handling/lv_b.bss.o(.bss);
        build/asm/data/mission_overlay/level_objective_handling/lv_c.bss.o(.bss);
        build/asm/data/mission_overlay/level_objective_handling/lv_d.bss.o(.bss);
        build/asm/data/mission_overlay/level_objective_handling/lv_e.bss.o(.bss);
        build/asm/data/mission_overlay/level_objective_handling/lv_f.bss.o(.bss);
        build/asm/data/mission_overlay/level_objective_handling/lv_g.bss.o(.bss);
        build/src/mission_overlay/level_objective_handling/lv_h.o(.bss);
        build/asm/data/mission_overlay/level_objective_handling/lv_i.bss.o(.bss);
        build/asm/data/mission_overlay/level_objective_handling/lv_k.bss.o(.bss);
        build/src/mission_overlay/level_objective_handling/lv_j.o(.bss);
        . = ALIGN(., 16);
        mission_overlay_BSS_END = .;
        mission_overlay_BSS_SIZE = ABSOLUTE(mission_overlay_BSS_END - mission_overlay_BSS_START);
    }
    __romPos += SIZEOF(.mission_overlay);
    __romPos = ALIGN(__romPos, 16);
    . = ALIGN(., 16);
    mission_overlay_ROM_SIZE = SIZEOF(.mission_overlay);
    mission_overlay_ROM_END = __romPos;
    mission_overlay_VRAM_END = .;

    menu_overlay_ROM_START = __romPos;
    menu_overlay_BASEROM_START = menu_overlay_ROM_START + 0xB0000000;
    menu_overlay_VRAM = ADDR(.menu_overlay);
    .menu_overlay 0x800A5130 : AT(menu_overlay_ROM_START) SUBALIGN(16)
    {
        FILL(0x00000000);
        menu_overlay_RODATA_START = .;
        build/src/menu_overlay/110410.o(.rodata);
        build/src/menu_overlay/115E00.o(.rodata);
        build/src/menu_overlay/1197D0.o(.rodata);
        build/src/menu_overlay/11B970.o(.rodata);
        build/src/menu_overlay/12CA40.o(.rodata);
        build/src/menu_overlay/jfif_handling.o(.rodata);
        build/src/menu_overlay/intro_crawl_handling.o(.rodata);
        build/src/menu_overlay/1331E0.o(.rodata);
        build/asm/data/menu_overlay/10EDA0.rodata.o(.rodata);
        . = ALIGN(., 16);
        menu_overlay_RODATA_END = .;
        menu_overlay_RODATA_SIZE = ABSOLUTE(menu_overlay_RODATA_END - menu_overlay_RODATA_START);
        menu_overlay_TEXT_START = .;
        build/src/menu_overlay/110410.o(.text);
        build/src/menu_overlay/115E00.o(.text);
        build/src/menu_overlay/1197D0.o(.text);
        build/src/menu_overlay/11B970.o(.text);
        build/src/menu_overlay/12CA40.o(.text);
        build/src/menu_overlay/jfif_handling.o(.text);
        build/src/menu_overlay/intro_crawl_handling.o(.text);
        build/src/menu_overlay/1331E0.o(.text);
        . = ALIGN(., 16);
        menu_overlay_TEXT_END = .;
        menu_overlay_TEXT_SIZE = ABSOLUTE(menu_overlay_TEXT_END - menu_overlay_TEXT_START);
        menu_overlay_DATA_START = .;
        build/asm/data/menu_overlay/110410.data.o(.data);
        build/asm/data/menu_overlay/115E00.data.o(.data);
        build/asm/data/menu_overlay/1197D0.data.o(.data);
        build/asm/data/menu_overlay/11B970.data.o(.data);
        build/asm/data/menu_overlay/12CA40.data.o(.data);
        build/src/menu_overlay/jfif_handling.o(.data);
        build/asm/data/menu_overlay/intro_crawl_handling.data.o(.data);
        build/src/menu_overlay/1331E0.o(.data);
        build/asm/data/menu_overlay/1346B0.data.o(.data);
        . = ALIGN(., 16);
        menu_overlay_DATA_END = .;
        menu_overlay_DATA_SIZE = ABSOLUTE(menu_overlay_DATA_END - menu_overlay_DATA_START);
    }
    menu_overlay_bss_VRAM = ADDR(.menu_overlay_bss);
    .menu_overlay_bss (NOLOAD) : SUBALIGN(16)
    {
        FILL(0x00000000);
        menu_overlay_BSS_START = .;
        build/asm/data/menu_overlay/110410.bss.o(.bss);
        build/asm/data/menu_overlay/115E00.bss.o(.bss);
        build/asm/data/menu_overlay/1197D0.bss.o(.bss);
        build/asm/data/menu_overlay/11B970.bss.o(.bss);
        build/asm/data/menu_overlay/12CA40.bss.o(.bss);
        build/src/menu_overlay/jfif_handling.o(.bss);
        build/asm/data/menu_overlay/intro_crawl_handling.bss.o(.bss);
        build/src/menu_overlay/1331E0.o(.bss);
        . = ALIGN(., 16);
        menu_overlay_BSS_END = .;
        menu_overlay_BSS_SIZE = ABSOLUTE(menu_overlay_BSS_END - menu_overlay_BSS_START);
    }
    __romPos += SIZEOF(.menu_overlay);
    __romPos = ALIGN(__romPos, 16);
    . = ALIGN(., 16);
    menu_overlay_ROM_SIZE = SIZEOF(.menu_overlay);
    menu_overlay_ROM_END = __romPos;
    menu_overlay_VRAM_END = .;

    _1346C0_ROM_START = __romPos;
    _1346C0_VRAM = ADDR(._1346C0);
    ._1346C0 : AT(_1346C0_ROM_START) SUBALIGN(16)
    {
        FILL(0x00000000);
        _1346C0_DATA_START = .;
        build/assets/1346C0.o(.data);
        _1346C0_DATA_END = .;
        _1346C0_DATA_SIZE = ABSOLUTE(_1346C0_DATA_END - _1346C0_DATA_START);
    }
    __romPos += SIZEOF(._1346C0);
    _1346C0_ROM_END = __romPos;
    _1346C0_VRAM_END = .;

    cinematic_overlay_ROM_START = __romPos;
    cinematic_overlay_BASEROM_START = cinematic_overlay_ROM_START + 0xB0000000;
    cinematic_overlay_VRAM = ADDR(.cinematic_overlay);
    .cinematic_overlay 0x800A5130 : AT(cinematic_overlay_ROM_START) SUBALIGN(16)
    {
        FILL(0x00000000);
        cinematic_overlay_RODATA_START = .;
        build/asm/data/cinematic_overlay/137580.rodata.o(.rodata);
        cinematic_overlay_TEXT_START = .;
        build/src/cinematic_overlay/1381D0.o(.text);
        . = ALIGN(., 16);
        cinematic_overlay_TEXT_END = .;
        cinematic_overlay_TEXT_SIZE = ABSOLUTE(cinematic_overlay_TEXT_END - cinematic_overlay_TEXT_START);
        cinematic_overlay_DATA_START = .;
        build/asm/data/cinematic_overlay/1381D0.data.o(.data);
        . = ALIGN(., 16);
        cinematic_overlay_DATA_END = .;
        cinematic_overlay_DATA_SIZE = ABSOLUTE(cinematic_overlay_DATA_END - cinematic_overlay_DATA_START);
        build/src/cinematic_overlay/1381D0.o(.rodata);
        . = ALIGN(., 16);
        cinematic_overlay_RODATA_END = .;
        cinematic_overlay_RODATA_SIZE = ABSOLUTE(cinematic_overlay_RODATA_END - cinematic_overlay_RODATA_START);
    }
    cinematic_overlay_bss_VRAM = ADDR(.cinematic_overlay_bss);
    .cinematic_overlay_bss (NOLOAD) : SUBALIGN(16)
    {
        FILL(0x00000000);
        cinematic_overlay_BSS_START = .;
        build/asm/data/cinematic_overlay/1381D0.bss.o(.bss);
        . = ALIGN(., 16);
        cinematic_overlay_BSS_END = .;
        cinematic_overlay_BSS_SIZE = ABSOLUTE(cinematic_overlay_BSS_END - cinematic_overlay_BSS_START);
    }
    __romPos += SIZEOF(.cinematic_overlay);
    __romPos = ALIGN(__romPos, 16);
    . = ALIGN(., 16);
    cinematic_overlay_ROM_END = __romPos;
    cinematic_overlay_ROM_SIZE = SIZEOF(.cinematic_overlay);
    cinematic_overlay_VRAM_END = .;

    _142D90_ROM_START = __romPos;
    _142D90_VRAM = ADDR(._142D90);
    ._142D90 : AT(_142D90_ROM_START) SUBALIGN(16)
    {
        FILL(0x00000000);
        _142D90_DATA_START = .;
        build/assets/142D90.o(.data);
        _142D90_DATA_END = .;
        _142D90_DATA_SIZE = ABSOLUTE(_142D90_DATA_END - _142D90_DATA_START);
    }
    __romPos += SIZEOF(._142D90);
    _142D90_ROM_END = __romPos;
    _142D90_VRAM_END = .;

    the_data_blob_ROM_START = __romPos;
    the_data_blob_VRAM = ADDR(.the_data_blob);
    .the_data_blob : AT(the_data_blob_ROM_START) SUBALIGN(16)
    {
        FILL(0x00000000);
        the_data_blob_DATA_START = .;
        build/assets/the_data_blob.o(.data);
        the_data_blob_DATA_END = .;
        the_data_blob_DATA_SIZE = ABSOLUTE(the_data_blob_DATA_END - the_data_blob_DATA_START);
    }
    __romPos += SIZEOF(.the_data_blob);
    the_data_blob_ROM_END = __romPos;
    the_data_blob_VRAM_END = .;

    main_bss_ROM_START = __romPos;
    main_bss_VRAM = ADDR(.main_bss);
    .main_bss 0x8010D200 : AT(main_bss_ROM_START) SUBALIGN(16)
    {
        FILL(0x00000000);
    }
    main_bss_bss_VRAM = ADDR(.main_bss_bss);
    .main_bss_bss (NOLOAD) : SUBALIGN(16)
    {
        FILL(0x00000000);
        main_bss_BSS_START = .;
        build/asm/data/main/8010D200.bss.o(.bss);
        build/asm/data/main/801128D0.bss.o(.bss);
        build/asm/data/main/801128E0.bss.o(.bss);
        build/asm/data/zlib/inftrees.bss.o(.bss);
        build/asm/data/libultra/io/conteepread.bss.o(.bss);
        build/asm/data/libultra/io/controller.bss.o(.bss);
        build/asm/data/libultra/os/initialize.bss.o(.bss);
        build/asm/data/libultra/debug/kdebugserver.bss.o(.bss);
        build/asm/data/libultra/io/leointerrupt.bss.o(.bss);
        build/asm/data/libultra/io/leodiskinit.bss.o(.bss);
        build/asm/data/libultra/io/motor.bss.o(.bss);
        build/asm/data/libultra/io/pfsisplug.bss.o(.bss);
        build/asm/data/libultra/io/pimgr.bss.o(.bss);
        build/asm/data/libultra/io/cartrominit.bss.o(.bss);
        build/asm/data/libultra/io/piacs.bss.o(.bss);
        build/asm/data/libultra/os/seteventmesg.bss.o(.bss);
        build/asm/data/libultra/io/siacs.bss.o(.bss);
        build/asm/data/libultra/io/sptask.bss.o(.bss);
        build/asm/data/libultra/os/timerintr.bss.o(.bss);
        build/asm/data/libultra/io/vimgr.bss.o(.bss);
        build/asm/data/main/80130B10.bss.o(.bss);
        build/src/main/3F160.o(.bss);
        build/asm/data/main/80130BD0.bss.o(.bss);
        main_bss_BSS_END = .;
        main_bss_BSS_SIZE = ABSOLUTE(main_bss_BSS_END - main_bss_BSS_START);
    }
    __romPos += SIZEOF(.main_bss);
    main_bss_ROM_END = __romPos;
    main_bss_VRAM_END = .;

    /DISCARD/ :
    {
        *(*);
    }
}
